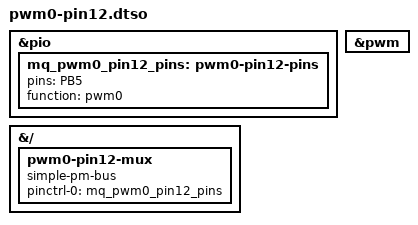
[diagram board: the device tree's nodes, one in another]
// SPDX-License-Identifier: (GPL-2.0+ OR MIT)
// Mangue OS header overlay pwm0-pin12 — GENERATED by tools/gen_overlays.py,
// edit overlays/header_table.py instead.
//
// pin port  role
//  12 PB5   pwm0
// device: /sys/class/pwm/pwmchip0 channel 0

/dts-v1/;
/plugin/;

#include <dt-bindings/gpio/gpio.h>
#include <dt-bindings/interrupt-controller/irq.h>
#include <dt-bindings/input/linux-event-codes.h>

&pio {
	mq_pwm0_pin12_pins: pwm0-pin12-pins {
		pins = "PB5";
		function = "pwm0";
	};
};

&pwm {
	status = "okay";
};

&{/} {
	pwm0-pin12-mux {
		compatible = "simple-pm-bus";
		pinctrl-names = "default";
		pinctrl-0 = <&mq_pwm0_pin12_pins>;
	};
};
